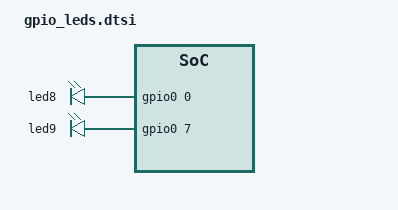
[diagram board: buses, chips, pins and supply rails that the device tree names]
/ {
	gpio-leds {
	    compatible = "gpio-leds";
	    led-8-yellow {
	        label = "led8";
	        gpios = <&gpio0 0 0>;
	        default-state = "off";
		linux,default-trigger = "mmc0";
	    };
	    led-9-red {
	        label = "led9";
	        gpios = <&gpio0 7 0>;
	        default-state = "off";
		linux,default-trigger = "hartbeat";
	    };
	};
};
